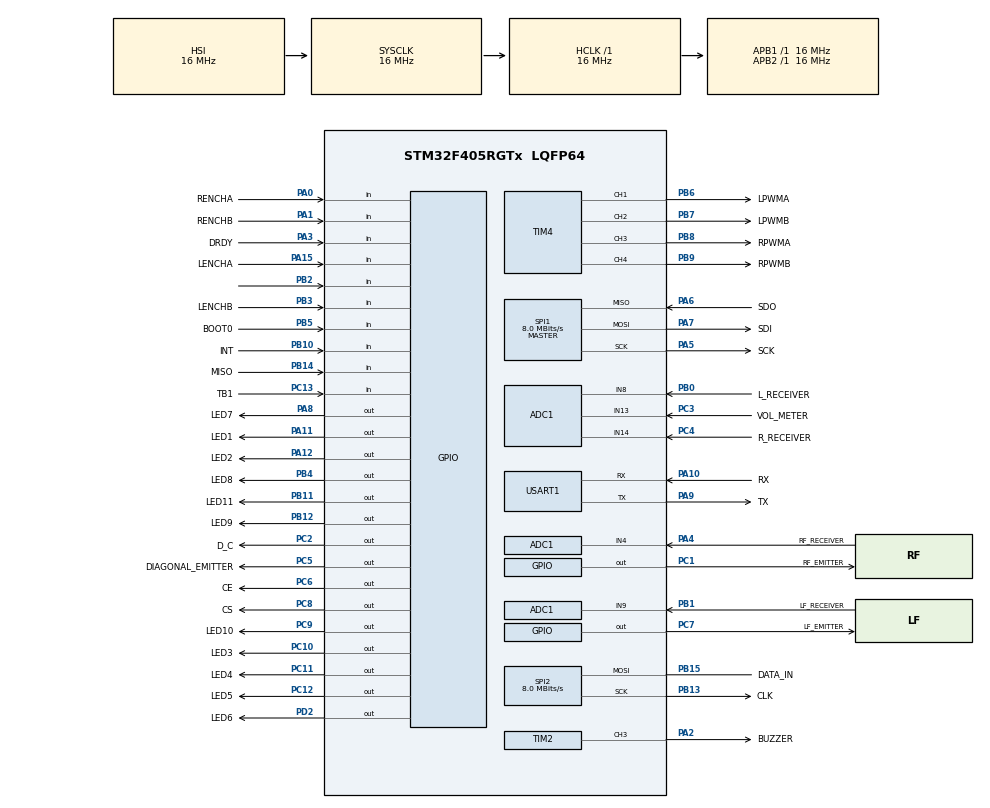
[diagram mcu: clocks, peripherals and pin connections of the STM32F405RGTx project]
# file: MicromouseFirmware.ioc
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ADC1.Channel-0\#ChannelRegularConversion=ADC_CHANNEL_4
ADC1.NbrOfConversionFlag=1
ADC1.Rank-0\#ChannelRegularConversion=1
ADC1.SamplingTime-0\#ChannelRegularConversion=ADC_SAMPLETIME_3CYCLES
ADC1.master=1
Mcu.Family=STM32F4
Mcu.Name=STM32F405RGTx
Mcu.Package=LQFP64
NVIC.PriorityGroup=NVIC_PRIORITYGROUP_4
PA0-WKUP.GPIO_Label=RENCHA
PA0-WKUP.Signal=GPIO_Input
PA1.GPIO_Label=RENCHB
PA1.Signal=GPIO_Input
PA10.GPIO_Label=RX
PA10.Mode=Asynchronous
PA10.Signal=USART1_RX
PA11.GPIO_Label=LED1
PA11.Signal=GPIO_Output
PA12.GPIO_Label=LED2
PA12.Signal=GPIO_Output
PA13.GPIO_Label=JTMS
PA13.Mode=Serial_Wire
PA13.Signal=SYS_JTMS-SWDIO
PA14.GPIO_Label=JTCK
PA14.Mode=Serial_Wire
PA14.Signal=SYS_JTCK-SWCLK
PA15.GPIO_Label=LENCHA
PA15.Signal=GPIO_Input
PA2.GPIO_Label=BUZZER
PA2.Signal=S_TIM2_CH3
PA3.GPIO_Label=DRDY
PA3.Signal=GPIO_Input
PA4.GPIO_Label=RF_RECEIVER
PA4.Signal=ADCx_IN4
PA5.GPIO_Label=SCK
PA5.Mode=Full_Duplex_Master
PA5.Signal=SPI1_SCK
PA6.GPIO_Label=SDO
PA6.Mode=Full_Duplex_Master
PA6.Signal=SPI1_MISO
PA7.GPIO_Label=SDI
PA7.Mode=Full_Duplex_Master
PA7.Signal=SPI1_MOSI
PA8.GPIO_Label=LED7
PA8.Signal=GPIO_Output
PA9.GPIO_Label=TX
PA9.Mode=Asynchronous
PA9.Signal=USART1_TX
PB0.GPIO_Label=L_RECEIVER
PB0.Signal=ADCx_IN8
PB1.GPIO_Label=LF_RECEIVER
PB1.Signal=ADCx_IN9
PB10.GPIO_Label=INT
PB10.Signal=GPIO_Input
PB11.GPIO_Label=LED11
PB11.Signal=GPIO_Output
PB12.GPIO_Label=LED9
PB12.Signal=GPIO_Output
PB13.GPIO_Label=CLK
PB13.Mode=Simplex_Bidirectional_Master
PB13.Signal=SPI2_SCK
PB14.GPIO_Label=MISO
PB14.Signal=GPIO_Input
PB15.GPIO_Label=DATA_IN
PB15.Mode=Simplex_Bidirectional_Master
PB15.Signal=SPI2_MOSI
PB2.Signal=GPIO_Input
PB3.GPIO_Label=LENCHB
PB3.Signal=GPIO_Input
PB4.GPIO_Label=LED8
PB4.Signal=GPIO_Output
PB5.GPIO_Label=BOOT0
PB5.Signal=GPIO_Input
PB6.GPIO_Label=LPWMA
PB6.Signal=S_TIM4_CH1
PB7.GPIO_Label=LPWMB
PB7.Signal=S_TIM4_CH2
PB8.GPIO_Label=RPWMA
PB8.Signal=S_TIM4_CH3
PB9.GPIO_Label=RPWMB
PB9.Signal=S_TIM4_CH4
PC1.GPIO_Label=RF_EMITTER
PC1.Signal=GPIO_Output
PC10.GPIO_Label=LED3
PC10.Signal=GPIO_Output
PC11.GPIO_Label=LED4
PC11.Signal=GPIO_Output
PC12.GPIO_Label=LED5
PC12.Signal=GPIO_Output
PC13-ANTI_TAMP.GPIO_Label=TB1
PC13-ANTI_TAMP.Signal=GPIO_Input
PC2.GPIO_Label=D_C
PC2.Signal=GPIO_Output
PC3.GPIO_Label=VOL_METER
PC3.Signal=ADCx_IN13
PC4.GPIO_Label=R_RECEIVER
PC4.Signal=ADCx_IN14
PC5.GPIO_Label=DIAGONAL_EMITTER
PC5.Signal=GPIO_Output
PC6.GPIO_Label=CE
PC6.Signal=GPIO_Output
PC7.GPIO_Label=LF_EMITTER
PC7.Signal=GPIO_Output
PC8.GPIO_Label=CS
PC8.Signal=GPIO_Output
PC9.GPIO_Label=LED10
PC9.Signal=GPIO_Output
PD2.GPIO_Label=LED6
PD2.Signal=GPIO_Output
PH0-OSC_IN.Mode=HSE-External-Oscillator
PH0-OSC_IN.Signal=RCC_OSC_IN
PH1-OSC_OUT.Mode=HSE-External-Oscillator
PH1-OSC_OUT.Signal=RCC_OSC_OUT
ProjectManager.HeapSize=0x200
ProjectManager.StackSize=0x400
ProjectManager.TargetToolchain=STM32CubeIDE
RCC.AHBFreq_Value=16000000
RCC.APB1Freq_Value=16000000
RCC.APB2Freq_Value=16000000
RCC.CortexFreq_Value=16000000
RCC.HSE_VALUE=25000000
RCC.HSI_VALUE=16000000
RCC.LSE_VALUE=32768
RCC.SYSCLKFreq_VALUE=16000000
RCC.VCOOutputFreq_Value=192000000
SH.ADCx_IN13.0=ADC1_IN13,IN13
SH.ADCx_IN14.0=ADC1_IN14,IN14
SH.ADCx_IN4.0=ADC1_IN4,IN4
SH.ADCx_IN8.0=ADC1_IN8,IN8
SH.ADCx_IN9.0=ADC1_IN9,IN9
SH.S_TIM2_CH3.0=TIM2_CH3,PWM Generation3 CH3
SH.S_TIM4_CH1.0=TIM4_CH1,PWM Generation1 CH1
SH.S_TIM4_CH2.0=TIM4_CH2,PWM Generation2 CH2
SH.S_TIM4_CH3.0=TIM4_CH3,PWM Generation3 CH3
SH.S_TIM4_CH4.0=TIM4_CH4,PWM Generation4 CH4
SPI1.CalculateBaudRate=8.0 MBits/s
SPI1.Direction=SPI_DIRECTION_2LINES
SPI1.Mode=SPI_MODE_MASTER
SPI1.VirtualType=VM_MASTER
SPI2.CalculateBaudRate=8.0 MBits/s
SPI2.Direction=SPI_DIRECTION_1LINE
SPI2.Mode=SPI_MODE_MASTER
SPI2.VirtualType=VM_MASTER
TIM2.Channel-PWM\ Generation3\ CH3=TIM_CHANNEL_3
TIM4.Channel-PWM\ Generation1\ CH1=TIM_CHANNEL_1
TIM4.Channel-PWM\ Generation2\ CH2=TIM_CHANNEL_2
TIM4.Channel-PWM\ Generation3\ CH3=TIM_CHANNEL_3
TIM4.Channel-PWM\ Generation4\ CH4=TIM_CHANNEL_4
USART1.VirtualMode=VM_ASYNC
VP_TIM4_VS_ClockSourceINT.Mode=Internal
board=custom

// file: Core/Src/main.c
/* USER CODE BEGIN Header */
/**
 ******************************************************************************
 * @file           : main.c
 * @brief          : Main program body
 ******************************************************************************
 * @attention
 *
 * Copyright (c) 2023 STMicroelectronics.
 * All rights reserved.
 *
 * This software is licensed under terms that can be found in the LICENSE file
 * in the root directory of this software component.
 * If no LICENSE file comes with this software, it is provided AS-IS.
 *
 ******************************************************************************
 */
/* USER CODE END Header */
#include "main.h"
#include "encoder.h"
#include "globals.h"

ADC_HandleTypeDef hadc1;

SPI_HandleTypeDef hspi1;
SPI_HandleTypeDef hspi2;

TIM_HandleTypeDef htim2;
TIM_HandleTypeDef htim4;

UART_HandleTypeDef huart1;

void SystemClock_Config(void);
static void MX_GPIO_Init(void);
static void MX_SPI1_Init(void);
static void MX_TIM4_Init(void);
static void MX_ADC1_Init(void);
static void MX_SPI2_Init(void);
static void MX_TIM2_Init(void);
static void MX_USART1_UART_Init(void);

int main(void) {

	/* MCU Configuration--------------------------------------------------------*/

	/* Reset of all peripherals, Initializes the Flash interface and the Systick. */
	HAL_Init();

	/* Configure the system clock */
	SystemClock_Config();

	/* Initialize all configured peripherals */
	MX_GPIO_Init();
	MX_SPI1_Init();
	MX_TIM4_Init();
	MX_ADC1_Init();
	MX_SPI2_Init();
	MX_TIM2_Init();
	MX_USART1_UART_Init();

	/* USER CODE BEGIN 2 */
	int32_t right_encoderPosition = 0;
	int32_t left_encoderPosition = 0;

	/* USER CODE END 2 */

	/* Infinite loop */
	while (1) {
		HAL_GPIO_TogglePin(LED1_GPIO_Port, LED1_Pin);
		HAL_Delay(100); /* Insert delay 100 ms */
		HAL_GPIO_TogglePin(LED2_GPIO_Port, LED2_Pin);
		HAL_Delay(100); /* Insert delay 100 ms */
		HAL_GPIO_TogglePin(LED3_GPIO_Port, LED3_Pin);
		HAL_Delay(100); /* Insert delay 100 ms */
		HAL_GPIO_TogglePin(LED4_GPIO_Port, LED4_Pin);
		HAL_Delay(100); /* Insert delay 100 ms */
		HAL_GPIO_TogglePin(LED5_GPIO_Port, LED5_Pin);
		HAL_Delay(100); /* Insert delay 100 ms */
		HAL_GPIO_TogglePin(LED6_GPIO_Port, LED6_Pin);
		HAL_Delay(100); /* Insert delay 100 ms */
		HAL_GPIO_TogglePin(LED7_GPIO_Port, LED7_Pin);
		HAL_Delay(100); /* Insert delay 100 ms */
		HAL_GPIO_TogglePin(LED8_GPIO_Port, LED8_Pin);
		HAL_Delay(100); /* Insert delay 100 ms */
		HAL_GPIO_TogglePin(LED9_GPIO_Port, LED9_Pin);
		HAL_Delay(100); /* Insert delay 100 ms */
		HAL_GPIO_TogglePin(LED10_GPIO_Port, LED10_Pin);
		HAL_Delay(100); /* Insert delay 100 ms */
		HAL_GPIO_TogglePin(LED11_GPIO_Port, LED11_Pin);
		HAL_Delay(100); /* Insert delay 100 ms */
	}
}

void SystemClock_Config(void) {
	RCC_OscInitTypeDef RCC_OscInitStruct = { 0 };
	RCC_ClkInitTypeDef RCC_ClkInitStruct = { 0 };

	/** Configure the main internal regulator output voltage
	 */
	__HAL_RCC_PWR_CLK_ENABLE();
	__HAL_PWR_VOLTAGESCALING_CONFIG(PWR_REGULATOR_VOLTAGE_SCALE1);

	/** Initializes the RCC Oscillators according to the specified parameters
	 * in the RCC_OscInitTypeDef structure.
	 */
	RCC_OscInitStruct.OscillatorType = RCC_OSCILLATORTYPE_HSI;
	RCC_OscInitStruct.HSIState = RCC_HSI_ON;
	RCC_OscInitStruct.HSICalibrationValue = RCC_HSICALIBRATION_DEFAULT;
	RCC_OscInitStruct.PLL.PLLState = RCC_PLL_NONE;
	if (HAL_RCC_OscConfig(&RCC_OscInitStruct) != HAL_OK) {
		Error_Handler();
	}

	/** Initializes the CPU, AHB and APB buses clocks
	 */
	RCC_ClkInitStruct.ClockType = RCC_CLOCKTYPE_HCLK | RCC_CLOCKTYPE_SYSCLK
			| RCC_CLOCKTYPE_PCLK1 | RCC_CLOCKTYPE_PCLK2;
	RCC_ClkInitStruct.SYSCLKSource = RCC_SYSCLKSOURCE_HSI;
	RCC_ClkInitStruct.AHBCLKDivider = RCC_SYSCLK_DIV1;
	RCC_ClkInitStruct.APB1CLKDivider = RCC_HCLK_DIV1;
	RCC_ClkInitStruct.APB2CLKDivider = RCC_HCLK_DIV1;

	if (HAL_RCC_ClockConfig(&RCC_ClkInitStruct, FLASH_LATENCY_0) != HAL_OK) {
		Error_Handler();
	}
}

static void MX_ADC1_Init(void) {

	ADC_ChannelConfTypeDef sConfig = { 0 };

	/** Configure the global features of the ADC (Clock, Resolution, Data Alignment and number of conversion)
	 */
	hadc1.Instance = ADC1;
	hadc1.Init.ClockPrescaler = ADC_CLOCK_SYNC_PCLK_DIV2;
	hadc1.Init.Resolution = ADC_RESOLUTION_12B;
	hadc1.Init.ScanConvMode = DISABLE;
	hadc1.Init.ContinuousConvMode = DISABLE;
	hadc1.Init.DiscontinuousConvMode = DISABLE;
	hadc1.Init.ExternalTrigConvEdge = ADC_EXTERNALTRIGCONVEDGE_NONE;
	hadc1.Init.ExternalTrigConv = ADC_SOFTWARE_START;
	hadc1.Init.DataAlign = ADC_DATAALIGN_RIGHT;
	hadc1.Init.NbrOfConversion = 1;
	hadc1.Init.DMAContinuousRequests = DISABLE;
	hadc1.Init.EOCSelection = ADC_EOC_SINGLE_CONV;
	if (HAL_ADC_Init(&hadc1) != HAL_OK) {
		Error_Handler();
	}

	/** Configure for the selected ADC regular channel its corresponding rank in the sequencer and its sample time.
	 */
	sConfig.Channel = ADC_CHANNEL_4;
	sConfig.Rank = 1;
	sConfig.SamplingTime = ADC_SAMPLETIME_3CYCLES;
	if (HAL_ADC_ConfigChannel(&hadc1, &sConfig) != HAL_OK) {
		Error_Handler();
	}

}

static void MX_SPI1_Init(void) {

	/* SPI1 parameter configuration*/
	hspi1.Instance = SPI1;
	hspi1.Init.Mode = SPI_MODE_MASTER;
	hspi1.Init.Direction = SPI_DIRECTION_2LINES;
	hspi1.Init.DataSize = SPI_DATASIZE_8BIT;
	hspi1.Init.CLKPolarity = SPI_POLARITY_LOW;
	hspi1.Init.CLKPhase = SPI_PHASE_1EDGE;
	hspi1.Init.NSS = SPI_NSS_SOFT;
	hspi1.Init.BaudRatePrescaler = SPI_BAUDRATEPRESCALER_2;
	hspi1.Init.FirstBit = SPI_FIRSTBIT_MSB;
	hspi1.Init.TIMode = SPI_TIMODE_DISABLE;
	hspi1.Init.CRCCalculation = SPI_CRCCALCULATION_DISABLE;
	hspi1.Init.CRCPolynomial = 10;
	if (HAL_SPI_Init(&hspi1) != HAL_OK) {
		Error_Handler();
	}

}

static void MX_SPI2_Init(void) {

	/* SPI2 parameter configuration*/
	hspi2.Instance = SPI2;
	hspi2.Init.Mode = SPI_MODE_MASTER;
	hspi2.Init.Direction = SPI_DIRECTION_1LINE;
	hspi2.Init.DataSize = SPI_DATASIZE_8BIT;
	hspi2.Init.CLKPolarity = SPI_POLARITY_LOW;
	hspi2.Init.CLKPhase = SPI_PHASE_1EDGE;
	hspi2.Init.NSS = SPI_NSS_SOFT;
	hspi2.Init.BaudRatePrescaler = SPI_BAUDRATEPRESCALER_2;
	hspi2.Init.FirstBit = SPI_FIRSTBIT_MSB;
	hspi2.Init.TIMode = SPI_TIMODE_DISABLE;
	hspi2.Init.CRCCalculation = SPI_CRCCALCULATION_DISABLE;
	hspi2.Init.CRCPolynomial = 10;
	if (HAL_SPI_Init(&hspi2) != HAL_OK) {
		Error_Handler();
	}

}

static void MX_TIM2_Init(void) {

	TIM_MasterConfigTypeDef sMasterConfig = { 0 };
	TIM_OC_InitTypeDef sConfigOC = { 0 };

	htim2.Instance = TIM2;
	htim2.Init.Prescaler = 0;
	htim2.Init.CounterMode = TIM_COUNTERMODE_UP;
	htim2.Init.Period = 4294967295;
	htim2.Init.ClockDivision = TIM_CLOCKDIVISION_DIV1;
	htim2.Init.AutoReloadPreload = TIM_AUTORELOAD_PRELOAD_DISABLE;
	if (HAL_TIM_PWM_Init(&htim2) != HAL_OK) {
		Error_Handler();
	}
	sMasterConfig.MasterOutputTrigger = TIM_TRGO_RESET;
	sMasterConfig.MasterSlaveMode = TIM_MASTERSLAVEMODE_DISABLE;
	if (HAL_TIMEx_MasterConfigSynchronization(&htim2, &sMasterConfig)
			!= HAL_OK) {
		Error_Handler();
	}
	sConfigOC.OCMode = TIM_OCMODE_PWM1;
	sConfigOC.Pulse = 0;
	sConfigOC.OCPolarity = TIM_OCPOLARITY_HIGH;
	sConfigOC.OCFastMode = TIM_OCFAST_DISABLE;
	if (HAL_TIM_PWM_ConfigChannel(&htim2, &sConfigOC, TIM_CHANNEL_3)
			!= HAL_OK) {
		Error_Handler();
	}
	HAL_TIM_MspPostInit(&htim2);

}

static void MX_TIM4_Init(void) {

	TIM_ClockConfigTypeDef sClockSourceConfig = { 0 };
	TIM_MasterConfigTypeDef sMasterConfig = { 0 };
	TIM_OC_InitTypeDef sConfigOC = { 0 };

	htim4.Instance = TIM4;
	htim4.Init.Prescaler = 0;
	htim4.Init.CounterMode = TIM_COUNTERMODE_UP;
	htim4.Init.Period = 65535;
	htim4.Init.ClockDivision = TIM_CLOCKDIVISION_DIV1;
	htim4.Init.AutoReloadPreload = TIM_AUTORELOAD_PRELOAD_DISABLE;
	if (HAL_TIM_Base_Init(&htim4) != HAL_OK) {
		Error_Handler();
	}
	sClockSourceConfig.ClockSource = TIM_CLOCKSOURCE_INTERNAL;
	if (HAL_TIM_ConfigClockSource(&htim4, &sClockSourceConfig) != HAL_OK) {
		Error_Handler();
	}
	if (HAL_TIM_PWM_Init(&htim4) != HAL_OK) {
		Error_Handler();
	}
	sMasterConfig.MasterOutputTrigger = TIM_TRGO_RESET;
	sMasterConfig.MasterSlaveMode = TIM_MASTERSLAVEMODE_DISABLE;
	if (HAL_TIMEx_MasterConfigSynchronization(&htim4, &sMasterConfig)
			!= HAL_OK) {
		Error_Handler();
	}
	sConfigOC.OCMode = TIM_OCMODE_PWM1;
	sConfigOC.Pulse = 0;
	sConfigOC.OCPolarity = TIM_OCPOLARITY_HIGH;
	sConfigOC.OCFastMode = TIM_OCFAST_DISABLE;
	if (HAL_TIM_PWM_ConfigChannel(&htim4, &sConfigOC, TIM_CHANNEL_1)
			!= HAL_OK) {
		Error_Handler();
	}
	if (HAL_TIM_PWM_ConfigChannel(&htim4, &sConfigOC, TIM_CHANNEL_2)
			!= HAL_OK) {
		Error_Handler();
	}
	if (HAL_TIM_PWM_ConfigChannel(&htim4, &sConfigOC, TIM_CHANNEL_3)
			!= HAL_OK) {
		Error_Handler();
	}
	if (HAL_TIM_PWM_ConfigChannel(&htim4, &sConfigOC, TIM_CHANNEL_4)
			!= HAL_OK) {
		Error_Handler();
	}
	HAL_TIM_MspPostInit(&htim4);

}

static void MX_USART1_UART_Init(void) {

	huart1.Instance = USART1;
	huart1.Init.BaudRate = 115200;
	huart1.Init.WordLength = UART_WORDLENGTH_8B;
	huart1.Init.StopBits = UART_STOPBITS_1;
	huart1.Init.Parity = UART_PARITY_NONE;
	huart1.Init.Mode = UART_MODE_TX_RX;
	huart1.Init.HwFlowCtl = UART_HWCONTROL_NONE;
	huart1.Init.OverSampling = UART_OVERSAMPLING_16;
	if (HAL_UART_Init(&huart1) != HAL_OK) {
		Error_Handler();
	}

}

static void MX_GPIO_Init(void) {
	GPIO_InitTypeDef GPIO_InitStruct = { 0 };

	/* GPIO Ports Clock Enable */
	__HAL_RCC_GPIOC_CLK_ENABLE();
	__HAL_RCC_GPIOH_CLK_ENABLE();
	__HAL_RCC_GPIOA_CLK_ENABLE();
	__HAL_RCC_GPIOB_CLK_ENABLE();
	__HAL_RCC_GPIOD_CLK_ENABLE();

	/*Configure GPIO pin Output Level */
	HAL_GPIO_WritePin(GPIOC,
			RF_EMITTER_Pin | D_C_Pin | DIAGONAL_EMITTER_Pin | CE_Pin
					| LF_EMITTER_Pin | CS_Pin | LED10_Pin | LED3_Pin | LED4_Pin
					| LED5_Pin, GPIO_PIN_RESET);

	/*Configure GPIO pin Output Level */
	HAL_GPIO_WritePin(GPIOB, LED11_Pin | LED9_Pin | LED8_Pin, GPIO_PIN_RESET);

	/*Configure GPIO pin Output Level */
	HAL_GPIO_WritePin(GPIOA, LED7_Pin | LED1_Pin | LED2_Pin, GPIO_PIN_RESET);

	/*Configure GPIO pin Output Level */
	HAL_GPIO_WritePin(LED6_GPIO_Port, LED6_Pin, GPIO_PIN_RESET);

	/*Configure GPIO pin : TB1_Pin */
	GPIO_InitStruct.Pin = TB1_Pin;
	GPIO_InitStruct.Mode = GPIO_MODE_INPUT;
	GPIO_InitStruct.Pull = GPIO_NOPULL;
	HAL_GPIO_Init(TB1_GPIO_Port, &GPIO_InitStruct);

	/*Configure GPIO pins : RF_EMITTER_Pin D_C_Pin DIAGONAL_EMITTER_Pin CE_Pin
	 LF_EMITTER_Pin CS_Pin LED10_Pin LED3_Pin
	 LED4_Pin LED5_Pin */
	GPIO_InitStruct.Pin = RF_EMITTER_Pin | D_C_Pin | DIAGONAL_EMITTER_Pin
			| CE_Pin | LF_EMITTER_Pin | CS_Pin | LED10_Pin | LED3_Pin | LED4_Pin
			| LED5_Pin;
	GPIO_InitStruct.Mode = GPIO_MODE_OUTPUT_PP;
	GPIO_InitStruct.Pull = GPIO_NOPULL;
	GPIO_InitStruct.Speed = GPIO_SPEED_FREQ_LOW;
	HAL_GPIO_Init(GPIOC, &GPIO_InitStruct);

	/*Configure GPIO pins : RENCHA_Pin RENCHB_Pin DRDY_Pin LENCHA_Pin */
	GPIO_InitStruct.Pin = RENCHA_Pin | RENCHB_Pin | DRDY_Pin | LENCHA_Pin;
	GPIO_InitStruct.Mode = GPIO_MODE_INPUT;
	GPIO_InitStruct.Pull = GPIO_NOPULL;
	HAL_GPIO_Init(GPIOA, &GPIO_InitStruct);

	/*Configure GPIO pins : PB2 INT_Pin MISO_Pin LENCHB_Pin
	 BOOT0_Pin */
	GPIO_InitStruct.Pin = GPIO_PIN_2 | INT_Pin | MISO_Pin | LENCHB_Pin
			| BOOT0_Pin;
	GPIO_InitStruct.Mode = GPIO_MODE_INPUT;
	GPIO_InitStruct.Pull = GPIO_NOPULL;
	HAL_GPIO_Init(GPIOB, &GPIO_InitStruct);

	/*Configure GPIO pins : LED11_Pin LED9_Pin LED8_Pin */
	GPIO_InitStruct.Pin = LED11_Pin | LED9_Pin | LED8_Pin;
	GPIO_InitStruct.Mode = GPIO_MODE_OUTPUT_PP;
	GPIO_InitStruct.Pull = GPIO_NOPULL;
	GPIO_InitStruct.Speed = GPIO_SPEED_FREQ_LOW;
	HAL_GPIO_Init(GPIOB, &GPIO_InitStruct);

	/*Configure GPIO pins : LED7_Pin LED1_Pin LED2_Pin */
	GPIO_InitStruct.Pin = LED7_Pin | LED1_Pin | LED2_Pin;
	GPIO_InitStruct.Mode = GPIO_MODE_OUTPUT_PP;
	GPIO_InitStruct.Pull = GPIO_NOPULL;
	GPIO_InitStruct.Speed = GPIO_SPEED_FREQ_LOW;
	HAL_GPIO_Init(GPIOA, &GPIO_InitStruct);

	/*Configure GPIO pin : LED6_Pin */
	GPIO_InitStruct.Pin = LED6_Pin;
	GPIO_InitStruct.Mode = GPIO_MODE_OUTPUT_PP;
	GPIO_InitStruct.Pull = GPIO_NOPULL;
	GPIO_InitStruct.Speed = GPIO_SPEED_FREQ_LOW;
	HAL_GPIO_Init(LED6_GPIO_Port, &GPIO_InitStruct);

}

void Error_Handler(void) {
	__disable_irq();
	while (1) {
	}
}
